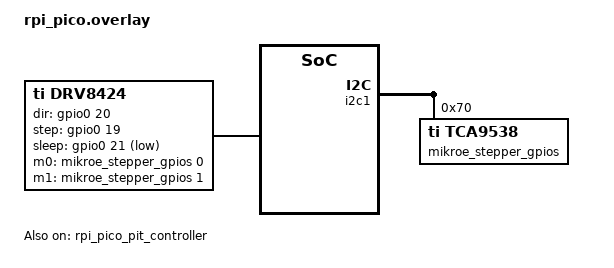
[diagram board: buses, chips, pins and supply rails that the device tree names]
/*
 * Copyright (c) 2024 Navimatix GmbH
 * SPDX-License-Identifier: Apache-2.0
 */

 #include <zephyr/dt-bindings/gpio/gpio.h>

&i2c1 {
	status = "okay";

	mikroe_stepper_gpios: mikroe_stepper_ctrl_tca9538a@70 {
		status = "okay";
		compatible = "ti,tca9538";

		reg = <0x70>;

		gpio-controller;
		ngpios = <8>;
		#gpio-cells = <2>;

		gpio-reserved-ranges = <7 1>;

		gpio-line-names =
			"M0",
			"M1",
			"DEC0",
			"DEC1",
			"TOFF",
			"STP",
			"DIR";
	};
};

/ {

	drv8424: drv8424 {
		status = "okay";
		compatible = "ti,drv8424";


		dir-gpios = <&gpio0 20 0 >;
		step-gpios = <&gpio0 19 0 >;
		sleep-gpios = <&gpio0 21 GPIO_ACTIVE_LOW>;
		m0-gpios = <&mikroe_stepper_gpios 0 0>;
		m1-gpios = <&mikroe_stepper_gpios 1 0>;
		counter = <&rpi_pico_pit_channel>;
	 };
};

/ {
	soc{
		rpi_pico_pit_controller: rpi_pico_pit_controller@4005d000 {
			status = "okay";
			compatible = "raspberrypi,pico-pit";
			reg = <0x4005d000 0x1000>;
			clocks = <&clocks 0x5>;
			interrupts = <0x4 0x3>;
			interrupt-names = "PWM_IRQ_WRAP";
			#pico-pit-controller-cells = <0>;
			#address-cells = <1>;
			#size-cells = <0>;

			rpi_pico_pit_channel: rpi_pico_pit_channel@3 {
				status = "okay";
				compatible = "raspberrypi,pico-pit-channel";
				reg = <3>;

				#pico-pit-channel-cells = <0>;
			};
		};
	};
};
